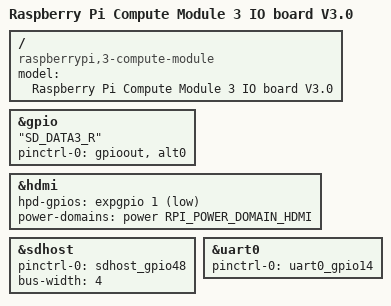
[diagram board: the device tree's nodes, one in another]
/* bench 25592.1.0 53571cfb7fb2 */
/* bench 25592.1.1 c3d3d2bc8467 */
/* bench 25592.1.2 58bab193a970 */
/* bench 25592.1.3 26713a7893e5 */
/* bench 25592.1.4 bb3f6dc396d7 */
/* bench 25592.1.5 9198e9701931 */
/* bench 25592.1.6 69d2a2816750 */
/* bench 25592.1.7 12ebe21b68f3 */
/dts-v1/;
#include "bcm2837-rpi-cm3.dtsi"
#include "bcm283x-rpi-usb-host.dtsi"

/ {
	compatible = "raspberrypi,3-compute-module", "brcm,bcm2837";
	model = "Raspberry Pi Compute Module 3 IO board V3.0";
};

&gpio {
	/*
	 * This is based on the official GPU firmware DT blob.
	 *
	 * Legend:
	 * "NC" = not connected (no rail from the SoC)
	 * "FOO" = GPIO line named "FOO" on the schematic
/* bench 23186.2.0 e1476d02812c */
/* bench 23186.2.1 fdf6be458936 */
/* bench 23186.2.2 91ff5c453269 */
/* bench 23186.2.3 4cdb6a8a5d86 */
/* bench 23186.2.4 d2d6aea4ffbb */
/* bench 23186.2.5 4ee0c9116c98 */
/* bench 23186.2.6 e91d33f98487 */
/* bench 23186.2.7 c15dbcc0a7cf */
/* bench 23186.2.8 d3284654b5b4 */
/* bench 23186.2.9 591347462dd5 */
/* bench 23186.2.10 d8c0caad408a */
/* bench 23186.2.11 620d3355bcf9 */
/* bench 23186.2.12 c665468bac2b */
			  "GPIO1",
			  "GPIO2",
			  "GPIO3",
			  "GPIO4",
			  "GPIO5",
			  "GPIO6",
			  "GPIO7",
			  "GPIO8",
			  "GPIO9",
			  "GPIO10",
			  "GPIO11",
			  "GPIO12",
			  "GPIO13",
			  "GPIO14",
			  "GPIO15",
			  "GPIO16",
			  "GPIO17",
			  "GPIO18",
			  "GPIO19",
			  "GPIO20",
			  "GPIO21",
			  "GPIO22",
			  "GPIO23",
			  "GPIO24",
			  "GPIO25",
/* bench 22170.1.0 5b1bf6233c23 */
/* bench 22170.1.1 0d7b71f7877a */
/* bench 22170.1.2 859220bacf33 */
/* bench 22170.1.3 4119703a3dba */
/* bench 22170.1.4 bee05e47440a */
			  "GPIO29",
			  "GPIO30",
			  "GPIO31",
			  "GPIO32",
			  "GPIO33",
			  "GPIO34",
			  "GPIO35",
			  "GPIO36",
			  "GPIO37",
			  "GPIO38",
			  "GPIO39",
			  "GPIO40",
			  "GPIO41",
			  "GPIO42",
			  "GPIO43",
			  "GPIO44",
			  "GPIO45",
			  "GPIO46",
			  "GPIO47",
			  /* Used by eMMC */
			  "SD_CLK_R",
			  "SD_CMD_R",
			  "SD_DATA0_R",
			  "SD_DATA1_R",
			  "SD_DATA2_R",
			  "SD_DATA3_R";

	pinctrl-0 = <&gpioout &alt0>;
};

&hdmi {
	hpd-gpios = <&expgpio 1 GPIO_ACTIVE_LOW>;
	power-domains = <&power RPI_POWER_DOMAIN_HDMI>;
	status = "okay";
};

&sdhost {
	pinctrl-names = "default";
	pinctrl-0 = <&sdhost_gpio48>;
	bus-width = <4>;
	status = "okay";
};

&uart0 {
	pinctrl-names = "default";
	pinctrl-0 = <&uart0_gpio14>;
	status = "okay";
};
